# ET6801 register map
Vendor: ETMCU Inc.; File version: v0.0.1
CPU: CM7 r2p1, little endian, MPU, FPU, I-cache, D-cache, ITCM, DTCM, 4 interrupt priority bits
Registers are 32-bit, read-write, reset 0x0 unless marked. A register's access mark holds for its fields unless they carry their own. Offsets are from the block's base; [hi:lo] are bit positions.

## CPU0 — Provide an overview of the purpose and functionality of the peripheral: m7_cfg
Base 0x40600000
Same registers: CPU1 0x40601000
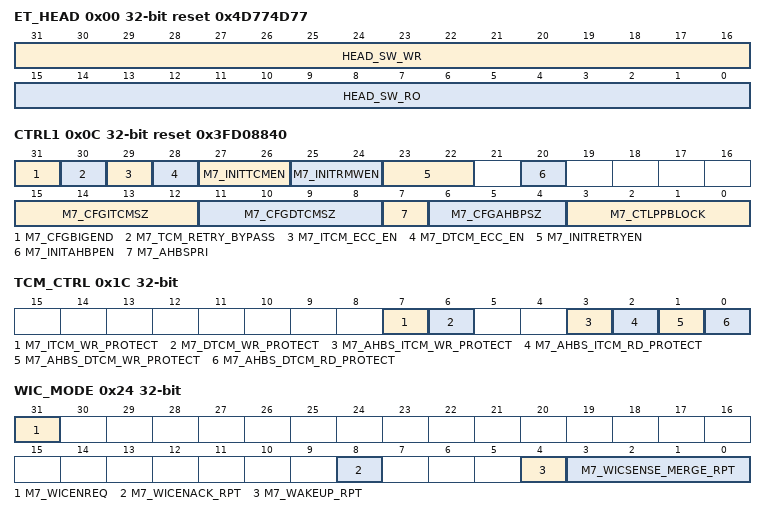
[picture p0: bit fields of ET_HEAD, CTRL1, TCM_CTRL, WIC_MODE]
0x00 ET_HEAD reset 0x4D774D77
  [31:16] HEAD_SW_WR — 软件测试读写寄存器，硬件无访问
  [15:0] HEAD_SW_RO ro — 软件只读上报寄存器，硬件无访问,M7的ASICII 码表示
0x04 KEY_CTRL reset 0x12345678
  [31:0] SW_ACCESS_KEY — 软件读写控制权限的KEY设置，只有KEY设置为0x7879a8a9，驱动软件才能访问相关软件可以访问的寄存器；否则会报总线访问错误；
0x08 RESERVE0
  [3:0] M7_RESERVE0 — 备用；
0x0C CTRL1 reset 0x3FD08840
  [31] M7_CFGBIGEND — sw_access_key设置为0x7879a8a9，才能更新该寄存器 1表示WORD中BYTE位置排布为大端模式，0表示WORD中BYTE位置排布小端模式，根据现有总线配置，要求固定按小端配置
  [30] M7_TCM_RETRY_BYPASS — itcm和dtcm retry时序路径bypass控制: 1'b1:itcm和dtcm返回的数据为ram读数据打1拍后的数据，且不返回retry； 1'b0:itcm和dtcm返回数据为ram直接读出的数据，下一拍返回retry给cpu，如果发生retry，接下来16拍cpu的读数据均是返回ram打1拍后的数据； 默认为1'b0,bypass不使能。
  [29] M7_ITCM_ECC_EN — sw_access_key设置为0x7879a8a9，才能更新该寄存器 1表示ITCM 64bit ECC模式使能
  [28] M7_DTCM_ECC_EN — sw_access_key设置为0x7879a8a9，才能更新该寄存器 1表示DTCM 32bit ECC模式使能
  [27:26] M7_INITTCMEN — sw_access_key设置为0x7879a8a9，才能更新该寄存器 bit0: 1表示ITCM初始使能，0表示不使能ITCM bit1: 1表示DTCM初始使能，0表示不使能DTCM
  [25:24] M7_INITRMWEN — sw_access_key设置为0x7879a8a9，才能更新该寄存器 bit0: 1表示ITCM初始使能Read-Modify-Write，如果使能ITCM ECC，该bit需要配置为1，0表示不使能 bit1: 1表示DTCM初始使能Read-Modify-Write，如果使能DTCM ECC，该bit需要配置为1，0表示不使能
  [23:22] M7_INITRETRYEN — sw_access_key设置为0x7879a8a9，才能更新该寄存器 bit0: 1表示ITCM初始使能Retry特性，如果使能ITCM ECC，该bit需要配置为1，0表示不使能 bit1: 1表示DTCM初始使能Retry特性，如果使能DTCM ECC，该bit需要配置为1，0表示不使能
  [20] M7_INITAHBPEN — sw_access_key设置为0x7879a8a9，才能更新该寄存器 1表示M7的AHBP口初始使能，0表示不使能
  [15:12] M7_CFGITCMSZ — sw_access_key设置为0x7879a8a9，才能更新该寄存器 ITCM SIZE参数配置配置 0b0000 No ITCM implemented. 0b0011 4KB. 0b0100 8KB. 0b0101 16KB. 0b0110 32KB. 0b0111 64KB. 0b1000 128KB. 0b1001 256KB. 0b1010 512KB. 0b1011 1MB. 0b1100 2MB. 0b1101 4MB. 0b1110 8MB. 0b1111 16MB.
  [11:8] M7_CFGDTCMSZ — sw_access_key设置为0x7879a8a9，才能更新该寄存器 DTCM SIZE参数配置配置 0b0000 No DTCM implemented. 0b0011 4KB. 0b0100 8KB. 0b0101 16KB. 0b0110 32KB. 0b0111 64KB. 0b1000 128KB. 0b1001 256KB. 0b1010 512KB. 0b1011 1MB. 0b1100 2MB. 0b1101 4MB. 0b1110 8MB. 0b1111 16MB.
  [7] M7_AHBSPRI — 1'b0 M7软件优先于总线AHBS访问TCM 1'b1总线AHBS优先于M7 软件访问TCM
  [6:4] M7_CFGAHBPSZ — sw_access_key设置为0x7879a8a9，才能更新该寄存器 M7 AHBP 可访问空间分配，超出该地址空间由M7的AXIM发出访问: 0b000 0MB. AHBP disabled. 0b001 64MB. 0b010 128MB. 0b011 256MB. 0b100 512MB.
  [3:0] M7_CTLPPBLOCK — sw_access_key设置为0x7879a8a9，才能更新该寄存器 When HIGH, 禁止 PPB 写 M7内部的 ITCMCR, DTCMCR, AHBPCR or VTOR 寄存器 每个bit映射关系为： [0] ITCMCR. [1] DTCMCR. [2] AHBPCR. [3] VTOR.
0x10 CTRL2
  [25:0] M7_CFGSTCALIB — sw_access_key设置为0x7879a8a9，才能更新该寄存器 配置方法参见cortex-M7的TRM手册
0x14 STCLK_DIV
  [7:0] M7_STCLK_DIV — sw_access_key设置为0x7879a8a9，才能更新该寄存器 当M7 CORE内部SYSTICK计数器采用外部计数使能时，该参数该计数使能产生是基于M7 CORE时钟的分频，0~255表示1~256分频。
0x18 TSCLKCHANGE
  [0] M7_TSCLKCHANGE — sw_access_key设置为0x7879a8a9，才能更新该寄存器 写1表示外部用于产生STCLKEN的计数时钟频率或者分频系数发生变化，写1 通知M7更新内部计数，硬件自清零
0x1C TCM_CTRL
  [7] M7_ITCM_WR_PROTECT — sw_access_key设置为0x7879a8a9，才能更新该寄存器 1表示对M7 内部局部总线访问ITCM做写保护，即是不允许通过M7 内部局部总线写ITCM，用于现场保护
  [6] M7_DTCM_WR_PROTECT — sw_access_key设置为0x7879a8a9，才能更新该寄存器 1表示对M7 内部局部总线访问DTCM做写保护，即是不允许通过M7 内部局部总线写DTCM，用于现场保护
  [3] M7_AHBS_ITCM_WR_PROTECT — sw_access_key设置为0x7879a8a9，才能更新该寄存器 1表示对M7 AHBS口访问ITCM做写保护，即是不允许通过M7 AHBS口写ITCM
  [2] M7_AHBS_ITCM_RD_PROTECT — sw_access_key设置为0x7879a8a9，才能更新该寄存器 1表示对M7 AHBS口访问ITCM做读保护，即是不允许通过M7 AHBS口读ITCM
  [1] M7_AHBS_DTCM_WR_PROTECT — sw_access_key设置为0x7879a8a9，才能更新该寄存器 1表示对M7 AHBS口访问DTCM做写保护，即是不允许通过M7 AHBS口写DTCM
  [0] M7_AHBS_DTCM_RD_PROTECT — sw_access_key设置为0x7879a8a9，才能更新该寄存器 1表示对M7 AHBS口访问DTCM做读保护，即是不允许通过M7 AHBS口读DTCM
0x20 IRQ_SYNC ro
  [0] M7_IRQ_LEVEL_SYNCED_RPT — 当前所有IRQ中断或起来的状态信号上报
0x24 WIC_MODE
  [31] M7_WICENREQ — sw_access_key设置为0x7879a8a9，才能更新该寄存器 1表示当前SLEEP过程采用WIC唤醒；0表示当前SLEEP采用NVIC唤醒
  [8] M7_WICENACK_RPT ro — 当前M7 WICENACK状态上报
  [4] M7_WAKEUP_RPT ro — 当前M7 WAKEUP状态上报
  [3:0] M7_WICSENSE_MERGE_RPT ro — 当前WIC唤醒的来源说明
0x28 RESERVE1
  [3:0] M7_RESERVE1 — Reserve sw_access_key设置为0x7879a8a9，才能更新该寄存器
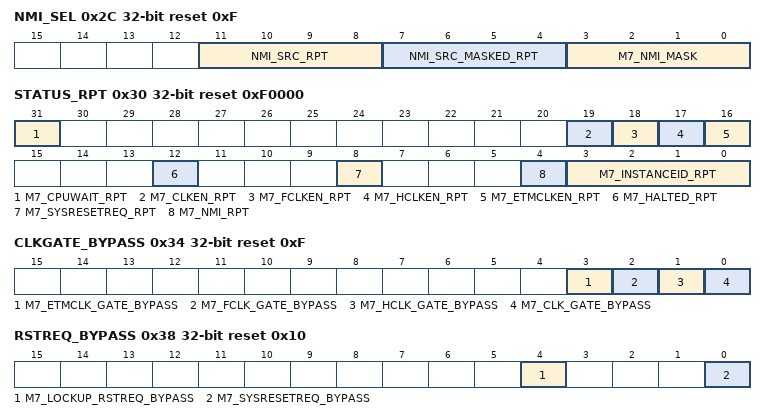
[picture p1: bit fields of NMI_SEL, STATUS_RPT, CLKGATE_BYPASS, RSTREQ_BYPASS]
0x2C NMI_SEL reset 0xF
  [11:8] NMI_SRC_RPT ro — 当前屏蔽前的四路NMI中断源状态信号
  [7:4] NMI_SRC_MASKED_RPT ro — 当前屏蔽后的四路NMI中断源状态信号
  [3:0] M7_NMI_MASK — sw_access_key设置为0x7879a8a9，才能更新该寄存器 M7的NMI中断源屏蔽控制信号
0x30 STATUS_RPT ro reset 0xF0000
  [31] M7_CPUWAIT_RPT — M7 CPUWAIT信号状态上报
  [19] M7_CLKEN_RPT — M7 CLKEN信号状态上报
  [18] M7_FCLKEN_RPT — M7 FCLKEN信号状态上报
  [17] M7_HCLKEN_RPT — M7 HCLKEN信号状态上报
  [16] M7_ETMCLKEN_RPT — M7 ETMCLKEN信号状态上报
  [12] M7_HALTED_RPT — M7 HALTED信号状态上报
  [8] M7_SYSRESETREQ_RPT — M7 SYSRESETREQ信号状态上报
  [4] M7_NMI_RPT — M7 NMI中断信号状态上报
  [3:0] M7_INSTANCEID_RPT — 当前M7 INSTANCE ID信号状态上报
0x34 CLKGATE_BYPASS reset 0xF
  [3] M7_ETMCLK_GATE_BYPASS — sw_access_key设置为0x7879a8a9，才能更新该寄存器 1表示旁路M7 ETMCLK 硬件GATING功能 0表示允许M7 ETMCLK 硬件GATING功能
  [2] M7_FCLK_GATE_BYPASS — sw_access_key设置为0x7879a8a9，才能更新该寄存器 1表示旁路M7 FCLK 硬件GATING功能 0表示允许M7 FLLK 硬件GATING功能
  [1] M7_HCLK_GATE_BYPASS — sw_access_key设置为0x7879a8a9，才能更新该寄存器 1表示旁路M7 HCLK 硬件GATING功能 0表示允许M7 HCLK 硬件GATING功能
  [0] M7_CLK_GATE_BYPASS — sw_access_key设置为0x7879a8a9，才能更新该寄存器 1表示旁路M7 CLK 硬件GATING功能 0表示允许M7 CLK 硬件GATING功能
0x38 RSTREQ_BYPASS reset 0x10
  [4] M7_LOCKUP_RSTREQ_BYPASS — sw_access_key设置为0x7879a8a9，才能更新该寄存器 1表示旁路M7 LOCKUP产生CORE复位请求功能 0表示允许M7 LOCKUP产生CORE复位请求
  [0] M7_SYSRESETREQ_BYPASS — sw_access_key设置为0x7879a8a9，才能更新该寄存器 1表示旁路M7 SYSRESETREQ产生CORE复位请求功能 0表示允许M7 SYSRESETREQ产生CORE复位请求
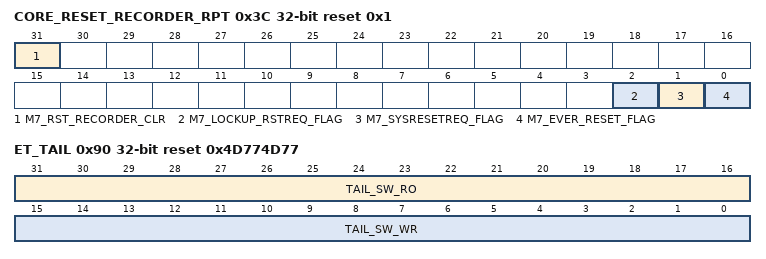
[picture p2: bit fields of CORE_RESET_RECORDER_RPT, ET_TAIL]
0x3C CORE_RESET_RECORDER_RPT reset 0x1
  [31] M7_RST_RECORDER_CLR — 写1 清除下列复位原因记录标志，硬件自清零
  [2] M7_LOCKUP_RSTREQ_FLAG ro — 1表示M7 LOCKUP产生CORE复位请求,并成功复位M7 CORE的标志记录
  [1] M7_SYSRESETREQ_FLAG ro — 1表示M7 SYSRESETREQ产生CORE复位请求,并成功复位M7 CORE的标志记录
  [0] M7_EVER_RESET_FLAG ro — 1表示M7 最近发生了M7 CORE复位
0x54 RESERVE0_RPT ro
  [3:0] M7_RESERVE0_RPT — Reserve使用
0x58 INT_EN
  [31:0] M7_INT_EN — 1表示使能M7 MISC逻辑中断;0 取消使能 Bit0: M7 AHBS ITCM禁止写时，有AHBS口写ITCM操作错误中断 Bit1: M7 AHBS ITCM禁止读时，有AHBS口读ITCM操作错误中断 Bit2: M7 AHBS DTCM禁止写时，有AHBS口写DTCM操作错误中断 Bit3: M7 AHBS DTCM禁止读时，有AHBS口读DTCM操作错误中断 Bit4: M7 ITCM LOCAL BUS禁止写，M7 ITCM LOCAL BUS写操作错误中断 Bit5: M7 DTCM LOCAL BUS禁止写，M7 DTCM LOCAL BUS写操作错误中断 Bit6: M7 AHBS未Ready，总线口有AHBS访问操作错误中断 Bit7: M7 AHBP BUFF写加速功能错误检测中断 Bit8：M7 DCACHE DATA部分有ECC 多bitFatal中断 Bit9：M7 DCACHE DATA部分有ECC 1bit 可纠错中断 Bit10：M7 DCACHE TAG部分有ECC 多bitFatal中断 Bit11：M7 DCACHE TAG部分有ECC 1bit 可纠错中断 Bit12：M7 D1TCM部分有ECC 多bitFatal中断 Bit13：M7 D1TCM部分有ECC 1bit 可纠错中断 Bit14：M7 D0TCM部分有ECC 多bitFatal中断 Bit15：M7 D0TCM部分有ECC 1bit 可纠错中断 Bit16：M7 ICACHE DATA部分有ECC 多bitFatal中断 Bit17：M7 ICACHE DATA部分有ECC 1bit 可纠错中断 Bit18：M7 ICACHE TAG部分有ECC 多bitFatal中断 Bit19：M7 ICACHE TAG部分有ECC 1bit 可纠错中断 Bit20：M7 ITCM部分有ECC 多bitFatal中断 Bit21：M7 ITCM部分有ECC 1bit 可纠错中断 Bit22：M7 FPU指令执行错误中断 Bit23：Reserve Bit24~31 Reserve
0x5C INT_MASK reset 0xFFFFFFFF
  [31:0] M7_INT_MASK — 1表示屏蔽M7 MISC逻辑中断;0 取消屏蔽 Bit0: M7 AHBS ITCM禁止写时，有AHBS口写ITCM操作错误中断 Bit1: M7 AHBS ITCM禁止读时，有AHBS口读ITCM操作错误中断 Bit2: M7 AHBS DTCM禁止写时，有AHBS口写DTCM操作错误中断 Bit3: M7 AHBS DTCM禁止读时，有AHBS口读DTCM操作错误中断 Bit4: M7 ITCM LOCAL BUS禁止写，M7 ITCM LOCAL BUS写操作错误中断 Bit5: M7 DTCM LOCAL BUS禁止写，M7 DTCM LOCAL BUS写操作错误中断 Bit6: M7 AHBS未Ready，总线口有AHBS访问操作错误中断 Bit7: M7 AHBP BUFF写加速功能错误检测中断 Bit8：M7 DCACHE DATA部分有ECC 多bitFatal中断 Bit9：M7 DCACHE DATA部分有ECC 1bit 可纠错中断 Bit10：M7 DCACHE TAG部分有ECC 多bitFatal中断 Bit11：M7 DCACHE TAG部分有ECC 1bit 可纠错中断 Bit12：M7 D1TCM部分有ECC 多bitFatal中断 Bit13：M7 D1TCM部分有ECC 1bit 可纠错中断 Bit14：M7 D0TCM部分有ECC 多bitFatal中断 Bit15：M7 D0TCM部分有ECC 1bit 可纠错中断 Bit16：M7 ICACHE DATA部分有ECC 多bitFatal中断 Bit17：M7 ICACHE DATA部分有ECC 1bit 可纠错中断 Bit18：M7 ICACHE TAG部分有ECC 多bitFatal中断 Bit19：M7 ICACHE TAG部分有ECC 1bit 可纠错中断 Bit20：M7 ITCM部分有ECC 多bitFatal中断 Bit21：M7 ITCM部分有ECC 1bit 可纠错中断 Bit22：M7 FPU指令执行错误中断 Bit23：Reserve Bit24~31 Reserve
0x60 INT_FORCE_IND
  [31:0] M7_INT_FORCE_IND — 1表示强制产生相应的测试中断，硬件自清零 Bit0: M7 AHBS ITCM禁止写时，有AHBS口写ITCM操作错误中断 Bit1: M7 AHBS ITCM禁止读时，有AHBS口读ITCM操作错误中断 Bit2: M7 AHBS DTCM禁止写时，有AHBS口写DTCM操作错误中断 Bit3: M7 AHBS DTCM禁止读时，有AHBS口读DTCM操作错误中断 Bit4: M7 ITCM LOCAL BUS禁止写，M7 ITCM LOCAL BUS写操作错误中断 Bit5: M7 DTCM LOCAL BUS禁止写，M7 DTCM LOCAL BUS写操作错误中断 Bit6: M7 AHBS未Ready，总线口有AHBS访问操作错误中断 Bit7: M7 AHBP BUFF写加速功能错误检测中断 Bit8：M7 DCACHE DATA部分有ECC 多bitFatal中断 Bit9：M7 DCACHE DATA部分有ECC 1bit 可纠错中断 Bit10：M7 DCACHE TAG部分有ECC 多bitFatal中断 Bit11：M7 DCACHE TAG部分有ECC 1bit 可纠错中断 Bit12：M7 D1TCM部分有ECC 多bitFatal中断 Bit13：M7 D1TCM部分有ECC 1bit 可纠错中断 Bit14：M7 D0TCM部分有ECC 多bitFatal中断 Bit15：M7 D0TCM部分有ECC 1bit 可纠错中断 Bit16：M7 ICACHE DATA部分有ECC 多bitFatal中断 Bit17：M7 ICACHE DATA部分有ECC 1bit 可纠错中断 Bit18：M7 ICACHE TAG部分有ECC 多bitFatal中断 Bit19：M7 ICACHE TAG部分有ECC 1bit 可纠错中断 Bit20：M7 ITCM部分有ECC 多bitFatal中断 Bit21：M7 ITCM部分有ECC 1bit 可纠错中断 Bit22：M7 FPU指令执行错误中断 Bit23：Reserve Bit24~31 Reserve
0x64 INT_CLR
  [31:0] M7_INT_CLR — 1表示清除相应的中断状态，硬件自清零 Bit0: M7 AHBS ITCM禁止写时，有AHBS口写ITCM操作错误中断 Bit1: M7 AHBS ITCM禁止读时，有AHBS口读ITCM操作错误中断 Bit2: M7 AHBS DTCM禁止写时，有AHBS口写DTCM操作错误中断 Bit3: M7 AHBS DTCM禁止读时，有AHBS口读DTCM操作错误中断 Bit4: M7 ITCM LOCAL BUS禁止写，M7 ITCM LOCAL BUS写操作错误中断 Bit5: M7 DTCM LOCAL BUS禁止写，M7 DTCM LOCAL BUS写操作错误中断 Bit6: M7 AHBS未Ready，总线口有AHBS访问操作错误中断 Bit7: M7 AHBP BUFF写加速功能错误检测中断 Bit8：M7 DCACHE DATA部分有ECC 多bitFatal中断 Bit9：M7 DCACHE DATA部分有ECC 1bit 可纠错中断 Bit10：M7 DCACHE TAG部分有ECC 多bitFatal中断 Bit11：M7 DCACHE TAG部分有ECC 1bit 可纠错中断 Bit12：M7 D1TCM部分有ECC 多bitFatal中断 Bit13：M7 D1TCM部分有ECC 1bit 可纠错中断 Bit14：M7 D0TCM部分有ECC 多bitFatal中断 Bit15：M7 D0TCM部分有ECC 1bit 可纠错中断 Bit16：M7 ICACHE DATA部分有ECC 多bitFatal中断 Bit17：M7 ICACHE DATA部分有ECC 1bit 可纠错中断 Bit18：M7 ICACHE TAG部分有ECC 多bitFatal中断 Bit19：M7 ICACHE TAG部分有ECC 1bit 可纠错中断 Bit20：M7 ITCM部分有ECC 多bitFatal中断 Bit21：M7 ITCM部分有ECC 1bit 可纠错中断 Bit22：M7 FPU指令执行错误中断 Bit23：Reserve Bit24~31 Reserve
0x68 INT_RAW_RPT ro
  [31:0] M7_INT_RAW_RPT — 中断MASK前RAW 中断状态上报 Bit0: M7 AHBS ITCM禁止写时，有AHBS口写ITCM操作错误中断 Bit1: M7 AHBS ITCM禁止读时，有AHBS口读ITCM操作错误中断 Bit2: M7 AHBS DTCM禁止写时，有AHBS口写DTCM操作错误中断 Bit3: M7 AHBS DTCM禁止读时，有AHBS口读DTCM操作错误中断 Bit4: M7 ITCM LOCAL BUS禁止写，M7 ITCM LOCAL BUS写操作错误中断 Bit5: M7 DTCM LOCAL BUS禁止写，M7 DTCM LOCAL BUS写操作错误中断 Bit6: M7 AHBS未Ready，总线口有AHBS访问操作错误中断 Bit7: M7 AHBP BUFF写加速功能错误检测中断 Bit8：M7 DCACHE DATA部分有ECC 多bitFatal中断 Bit9：M7 DCACHE DATA部分有ECC 1bit 可纠错中断 Bit10：M7 DCACHE TAG部分有ECC 多bitFatal中断 Bit11：M7 DCACHE TAG部分有ECC 1bit 可纠错中断 Bit12：M7 D1TCM部分有ECC 多bitFatal中断 Bit13：M7 D1TCM部分有ECC 1bit 可纠错中断 Bit14：M7 D0TCM部分有ECC 多bitFatal中断 Bit15：M7 D0TCM部分有ECC 1bit 可纠错中断 Bit16：M7 ICACHE DATA部分有ECC 多bitFatal中断 Bit17：M7 ICACHE DATA部分有ECC 1bit 可纠错中断 Bit18：M7 ICACHE TAG部分有ECC 多bitFatal中断 Bit19：M7 ICACHE TAG部分有ECC 1bit 可纠错中断 Bit20：M7 ITCM部分有ECC 多bitFatal中断 Bit21：M7 ITCM部分有ECC 1bit 可纠错中断 Bit22：M7 FPU指令执行错误中断 Bit23：Reserve Bit24~31 Reserve
0x6C INT_STATUS_RPT ro
  [31:0] M7_INT_STATUS_RPT — 中断MASK后中断状态上报 Bit0: M7 AHBS ITCM禁止写时，有AHBS口写ITCM操作错误中断 Bit1: M7 AHBS ITCM禁止读时，有AHBS口读ITCM操作错误中断 Bit2: M7 AHBS DTCM禁止写时，有AHBS口写DTCM操作错误中断 Bit3: M7 AHBS DTCM禁止读时，有AHBS口读DTCM操作错误中断 Bit4: M7 ITCM LOCAL BUS禁止写，M7 ITCM LOCAL BUS写操作错误中断 Bit5: M7 DTCM LOCAL BUS禁止写，M7 DTCM LOCAL BUS写操作错误中断 Bit6: M7 AHBS未Ready，总线口有AHBS访问操作错误中断 Bit7: Reserve Bit8：M7 DCACHE DATA部分有ECC 多bitFatal中断 Bit9：M7 DCACHE DATA部分有ECC 1bit 可纠错中断 Bit10：M7 DCACHE TAG部分有ECC 多bitFatal中断 Bit11：M7 DCACHE TAG部分有ECC 1bit 可纠错中断 Bit12：M7 D1TCM部分有ECC 多bitFatal中断 Bit13：M7 D1TCM部分有ECC 1bit 可纠错中断 Bit14：M7 D0TCM部分有ECC 多bitFatal中断 Bit15：M7 D0TCM部分有ECC 1bit 可纠错中断 Bit16：M7 ICACHE DATA部分有ECC 多bitFatal中断 Bit17：M7 ICACHE DATA部分有ECC 1bit 可纠错中断 Bit18：M7 ICACHE TAG部分有ECC 多bitFatal中断 Bit19：M7 ICACHE TAG部分有ECC 1bit 可纠错中断 Bit20：M7 ITCM部分有ECC 多bitFatal中断 Bit21：M7 ITCM部分有ECC 1bit 可纠错中断 Bit22：M7 FPU指令执行错误中断 Bit23：Reserve Bit24~31 Reserve
0x70 DCACHE_CTRLBUS_HIGH
  [31:0] DCACHE_CTRLBUS_HIGH — CPU0 DCACHE RAM CTRLBUS的高32bit配置值
0x74 DCACHE_CTRLBUS_LOW reset 0x9A9D1
  [31:0] DCACHE_CTRLBUS_LOW — CPU0 DCACHE RAM CTRLBUS的低32bit配置值
0x78 ICACHE_CTRLBUS_HIGH
  [31:0] ICACHE_CTRLBUS_HIGH — CPU0 ICACHE RAM CTRLBUS的高32bit配置值
0x7C ICACHE_CTRLBUS_LOW reset 0x9A9D1
  [31:0] ICACHE_CTRLBUS_LOW — CPU0 ICACHE RAM CTRLBUS的低32bit配置值
0x80 ITCM_CTRLBUS_HIGH
  [31:0] ITCM_CTRLBUS_HIGH — CPU0 ITCM地址空间最低1/4 部分RAM CTRLBUS的高32bit配置值
0x84 ITCM_CTRLBUS_LOW reset 0x9A9D1
  [31:0] ITCM_CTRLBUS_LOW — CPU0 ITCM 地址空间最低1/4 部分RAM CTRLBUS的低32bit配置值
0x88 DTCM_CTRLBUS_HIGH
  [31:0] DTCM_CTRLBUS_HIGH — CPU0 DTCM地址空间最低1/4 部分RAM CTRLBUS的高32bit配置值
0x8C DTCM_CTRLBUS_LOW reset 0x9A9D1
  [31:0] DTCM_CTRLBUS_LOW — CPU0 DTCM 地址空间最低1/4 部分RAM CTRLBUS的低32bit配置值
0x90 ET_TAIL reset 0x4D774D77
  [31:16] TAIL_SW_RO ro — 软件只读硬件上报寄存器
  [15:0] TAIL_SW_WR — 软件测试读写寄存器，硬件无访问
